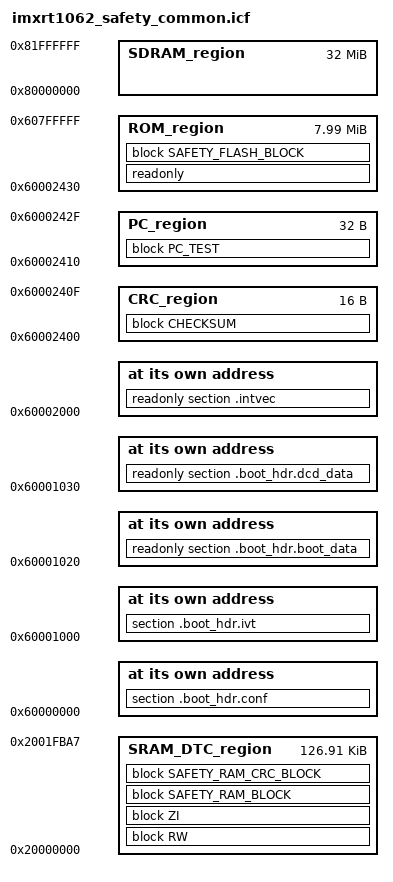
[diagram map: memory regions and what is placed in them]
/*
* Copyright (c) 2013 - 2016, Freescale Semiconductor, Inc.
* Copyright 2016-2019 NXP
*
* SPDX-License-Identifier: NXP Proprietary
*/

/******************************************************************************/
/******************     USER CONFIGURATION PART     ***************************/
/******************************************************************************/
define exported symbol stack_test_block_size = 0x10;
define exported symbol ram_test_backup_size  = 0x20;
define symbol __vector_table_size__          = 0x400;
define symbol __size_cstack__                = 0x0400;

define symbol SRAM_DTC_start       = 0x20000000; /* Part of 512KB on-chip RAM (Data-Tightly-Coupled) */
define symbol SRAM_DTC_end         = 0x2001FFFF;

define symbol ROM_interrupts_start = 0x60002000; /* IVT in ROM */
define symbol ROM_interrupts_end   = ROM_interrupts_start + __vector_table_size__ - 1;

define symbol __FlashCRC_start__   = 0x60002400; /* Place checksum result after IVT (in ROM) */
define symbol __FlashCRC_end__     = 0x6000240F;

define symbol __PC_test_start__    = 0x60002410; /* PC object address (pattern to PC:0x60002411) */
define symbol __PC_test_end__      = 0x6000242F; /* PC object reserved size: 0x20 */ 

define symbol ROM_start            = 0x60002430; /* ~64MB of ROM memory (external ROM) */
define symbol ROM_end              = 0x607FFFFF;

define symbol SDRAM_start          = 0x80000000; /* ~32MB of SDRAM memory (external RAM) */
define symbol SDRAM_end            = 0x81FFFFFF;

define exported symbol __VECTOR_TABLE = ROM_interrupts_start;

/***** XIP boot header start *****/
define exported symbol m_boot_hdr_conf_start = 0x60000000;
define symbol m_boot_hdr_ivt_start           = 0x60001000;
define symbol m_boot_hdr_boot_data_start     = 0x60001020;
define symbol m_boot_hdr_dcd_data_start      = 0x60001030;
/***** XIP boot header end *****/

/***** NOT USED IN THIS EXAMPLE *****/
define symbol SRAM_ITC_start       = 0x00000000; /* Part of 512KB on-chip RAM (Instruction-Tightly-Coupled) */
define symbol SRAM_ITC_end         = 0x0001FFFF;

define symbol SRAM_OC_start = 0x20200000; /* Part of 512KB on-chip RAM */
define symbol SRAM_OC_end   = 0x202BFFFF;
/***** NOT USED IN THIS EXAMPLE *****/

/******************************************************************************/
/******************     SYMBOLS     *******************************************/
/******************************************************************************/ 
define exported symbol m_ram_test_backup    = SRAM_DTC_end - ram_test_backup_size + 0x1;
define exported symbol m_wd_test_backup     = m_ram_test_backup - 0x10;
define exported symbol m_pc_test_flag       = m_wd_test_backup - 0x4;
define exported symbol m_safety_error_code  = m_pc_test_flag - 0x4;
define exported symbol m_stack_test_p_4     = m_safety_error_code - 0x4;
define exported symbol m_stack_test_p_3     = m_stack_test_p_4 - stack_test_block_size +0x4;
define exported symbol __BOOT_STACK_ADDRESS = m_stack_test_p_3 - 0x4;
define exported symbol m_stack_test_p_2     = __BOOT_STACK_ADDRESS - __size_cstack__;
define exported symbol m_stack_test_p_1     = m_stack_test_p_2 - stack_test_block_size + 0x4;
define symbol SRAM_DTC_end_edited           = m_stack_test_p_1 - 0x1;

/******************************************************************************/
/******************     REGIONS     *******************************************/
/******************************************************************************/
define memory mem with size   = 4G;
define region SRAM_DTC_region = mem:[from SRAM_DTC_start to SRAM_DTC_end_edited];
define region CRC_region      = mem:[from __FlashCRC_start__  to __FlashCRC_end__];
define region PC_region       = mem:[from __PC_test_start__ to __PC_test_end__];
define region ROM_region      = mem:[from ROM_start to ROM_end];
define region SDRAM_region    = mem:[from SDRAM_start to SDRAM_end];

/******************************************************************************/
/******************     SECTIONS & BLOCKS    **********************************/
/******************************************************************************/
initialize manually           { readwrite };
initialize manually           { section .data };
initialize manually           { section .bss };
initialize manually           { section .textrw };
initialize manually           { section .safety_ram };
initialize manually           { section .safety_ram_crc };
do not initialize             { section .noinit };

define block RW               { readwrite };
define block ZI               { zi };
define block PC_TEST          { section .text object iec60730b_cm4_cm7_pc_object.o };
define block CHECKSUM         { section .checksum };
define block SAFETY_RAM_BLOCK { section .safety_ram };
define block SAFETY_RAM_CRC_BLOCK { section .safety_ram_crc };
define block SAFETY_FLASH_BLOCK with fixed order
{
 readonly section checksum_start_mark,
 section .text         object  main.o,
 section .text         object  safety_cm4_cm7_imxrt.o,
 section .rodata       object  safety_cm4_cm7_imxrt.o,
 readonly section checksum_end_mark
};

/*****************************************************/
/******************     PLACING     ******************/
/*****************************************************/
/***** XIP boot header start *****/
place at address mem:m_boot_hdr_conf_start      { section .boot_hdr.conf };
place at address mem:m_boot_hdr_ivt_start       { section .boot_hdr.ivt };
place at address mem:m_boot_hdr_boot_data_start { readonly section .boot_hdr.boot_data };
place at address mem:m_boot_hdr_dcd_data_start  { readonly section .boot_hdr.dcd_data };
keep { section .boot_hdr.conf, section .boot_hdr.ivt, section .boot_hdr.boot_data, section .boot_hdr.dcd_data };
/***** XIP boot header end *****/

place at address mem:ROM_interrupts_start { readonly section .intvec };

place in ROM_region      { readonly };
place in ROM_region      { block SAFETY_FLASH_BLOCK};
place in CRC_region      { block CHECKSUM };
place in PC_region       { block PC_TEST};
place in SRAM_DTC_region { block RW, block ZI };
place in SRAM_DTC_region { block SAFETY_RAM_BLOCK };
place in SRAM_DTC_region { block SAFETY_RAM_CRC_BLOCK };
